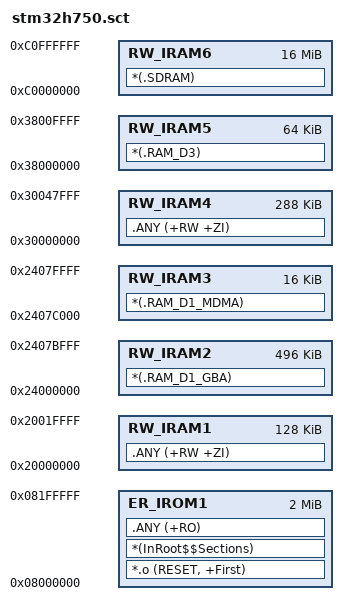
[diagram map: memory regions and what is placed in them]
; *************************************************************
; *** Scatter-Loading Description File generated by uVision ***
; *************************************************************

LR_IROM1 0x08000000 0x00200000  {    ; load region size_region
  ER_IROM1 0x08000000 0x00200000  {  ; load address = execution address
   *.o (RESET, +First)
   *(InRoot$$Sections)
   .ANY (+RO)
  }

  RW_IRAM1 0x20000000 0x00020000  {  ; RW data - 128KB DTCM
   .ANY (+RW +ZI)
  }
  
  RW_IRAM2 0x24000000 0x0007C000  {  ; RW data - 496KB AXI SRAM
   *(.RAM_D1_GBA) 
  }
  
  RW_IRAM3 0x2407C000 0x00004000  {  ; RW data - 16KB AXI SRAM
   *(.RAM_D1_MDMA) 
  }
  
  RW_IRAM4 0x30000000 0x00048000  {  ; RW data - 128KB SRAM1(0x30000000) + 128KB SRAM2(0x3002 0000) + 32KB SRAM3(0x30040000)
   .ANY (+RW +ZI)
  }
  
  RW_IRAM5 0x38000000 0x00010000  {  ; RW data - 64KB SRAM4(0x38000000)
   *(.RAM_D3) 
  }
  
  RW_IRAM6 0xC0000000 0x01000000  {  ; RW data
  *(.SDRAM)
  }
}
